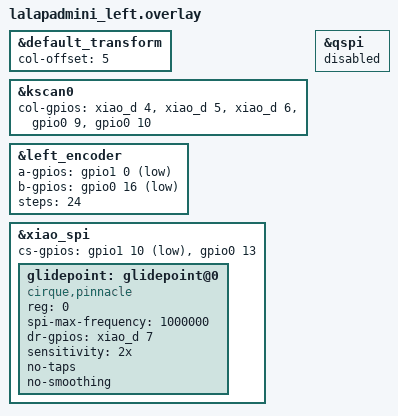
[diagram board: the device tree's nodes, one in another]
#include "lalapadmini.dtsi"

&default_transform {
    col-offset = <5>;
};

&kscan0 {
    col-gpios
        = <&xiao_d 4 GPIO_ACTIVE_HIGH>
        , <&xiao_d 5 GPIO_ACTIVE_HIGH>
        , <&xiao_d 6 GPIO_ACTIVE_HIGH>
        , <&gpio0  9 GPIO_ACTIVE_HIGH>
        , <&gpio0 10 GPIO_ACTIVE_HIGH>
        ;
};

&left_encoder {
    a-gpios = <&gpio1  0 (GPIO_ACTIVE_LOW | GPIO_PULL_UP)>;
    b-gpios = <&gpio0 16 (GPIO_ACTIVE_LOW | GPIO_PULL_UP)>;
    steps = <24>;
    status = "okay";
};
// SPI
&qspi {
	status = "disabled";
};
&xiao_spi {
    status = "okay";
    cs-gpios = <&gpio1 10 (GPIO_ACTIVE_LOW )>, <&gpio0 13 (GPIO_PULL_UP)>;//dummy

    glidepoint: glidepoint@0 {
        compatible = "cirque,pinnacle";
        status = "okay";
        reg = <0>;
        spi-max-frequency = <1000000>;
        dr-gpios = <&xiao_d 7 (GPIO_ACTIVE_HIGH)>;

        sensitivity = "2x";
        no-taps;
        no-smoothing;
    };
};
